# ADSP-2183xW_LPC register map
Vendor: Analog Devices; Series: ADSP-2183xW_LPC; File version: 3.0.3.517
CPU: 
Registers are 32-bit, read-write, reset 0x0 unless marked. A register's access mark holds for its fields unless they carry their own. Offsets are from the block's base; [hi:lo] are bit positions; {n}, {i} and the like mark numbered series; 'fields as' and 'values as' point back to an identical list.

## FIR0 — The FIR accelerator
Base 0x310C3000
Same registers: FIR1 0x310BF000
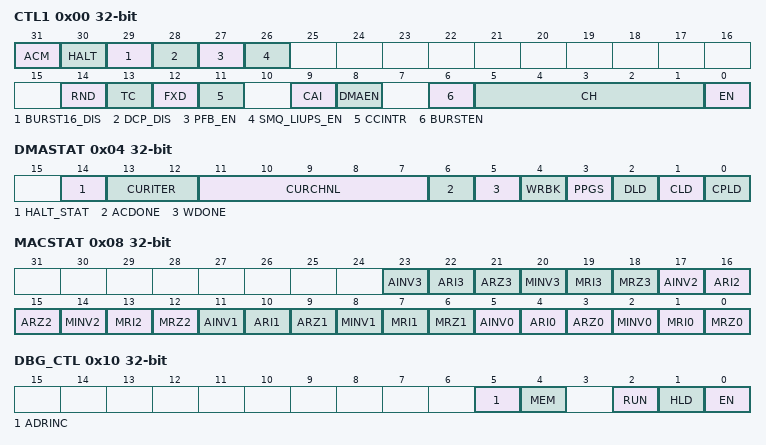
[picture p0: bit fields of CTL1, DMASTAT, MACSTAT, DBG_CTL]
0x00 CTL1 — FIR Global Control Register
  [31] ACM — Auto Configuration Mode
    0=LEGACY (Legacy Mode. Load TCB without the FIR_CTL1 register. Core intervention may be required.); 1=AUTOCONFIG (Auto Configuration Mode. Load TCB with the FIR_CTL1 register. Core intervention is not required.)
  [30] HALT — HALT (Pause Accelerator)
    0=RELEASE; 1=PAUSE
  [29] BURST16_DIS — Disable 16 Burst
  [28] DCP_DIS — Disable Data Coefficient Load in Parallel
  [27] PFB_EN — Enable PFB
  [26] SMQ_LIUPS_EN — Legacy I/P and O/P Index Update Scheme in SMART_Q Mode
  [14] RND — Rounding Mode
    0=TONEAREST (Round to Nearest); 1=TRUNCATE (Truncate (round towards zero))
  [13] TC — Two's-Complement
  [12] FXD — Fixed-Point Accelerator Select
  [11] CCINTR — Channel Complete Interrupt
  [9] CAI — Channel Auto Iterate
  [8] DMAEN — DMA Enable
  [6] BURSTEN range 0x00000000..0x00000001 — Burst Mode Select
  [5:1] CH — Number of Channels
  [0] EN — FIR Enable
0x04 DMASTAT — FIR DMA Status Register
  [14] HALT_STAT ro — Accelerator HALT Status
  [13:12] CURITER ro — Current MAC Iteration
  [11:7] CURCHNL ro — Current Channel
  [6] ACDONE ro — All Channels Done
  [5] WDONE ro — Channel Done
  [4] WRBK ro — Writing Back
  [3] PPGS ro — MAC Processing in Progress
  [2] DLD ro — Data Preload
  [1] CLD ro — Coefficient Loading
  [0] CPLD ro — Chain Pointer Loading Status
0x08 MACSTAT — FIR MAC Status Register
  [6n+5] AINV{n} ro (n=0..3) — Addition Invalid
  [6n+4] ARI{n} ro (n=0..3) — Adder Result Overflow
  [6n+3] ARZ{n} ro (n=0..3) — Adder Result Underflow
  [6n+2] MINV{n} ro (n=0..3) — Multiply Invalid
  [6n+1] MRI{n} ro (n=0..3) — Multiplier Result Overflow
  [6n] MRZ{n} ro (n=0..3) — Multiplier Result Underflow
0x10 DBG_CTL — FIR Debug Control Register
  [5] ADRINC range 0x00000000..0x00000001 — Address Auto Increment
  [4] MEM range 0x00000000..0x00000001 — Local Memory Access
  [2] RUN range 0x00000000..0x00000001 — Release MAC
  [1] HLD — Hold
  [0] EN — Debug Mode Enable
0x14 DBG_ADDR — Debug Address Register
  [10:0] VALUE range 0x00000000..0x000007FF — Debug Address, Coefficient Memory Select
0x18 DBG_WRDAT — FIR Debug Data Write Register
  [31:0] VALUE range 0x00000000..0xFFFFFFFF — Debug Write Data
0x1C DBG_RDDAT — FIR Debug Data Read Register
  [31:0] VALUE range 0x00000000..0xFFFFFFFF — Debug Read Data
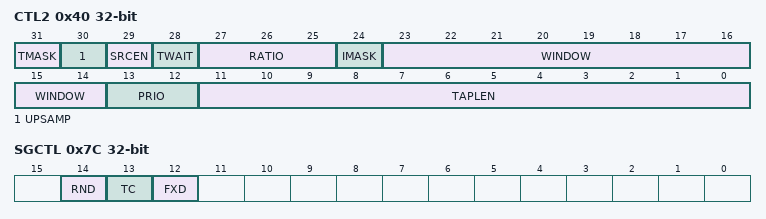
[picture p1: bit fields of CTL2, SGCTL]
0x40 CTL2 — FIR Channel Control Register
  [31] TMASK — Trigger Mask
    0=TMASK_EN (Enable); 1=TMASK_DIS (Mask)
  [30] UPSAMP — Up Sampling Enable
  [29] SRCEN — Sample Rate Conversion Enable
  [28] TWAIT — Wait for Trigger
    0=DIS (Disable wait for trigger for the channel); 1=ENA (Enable wait for the external trigger assertion)
  [27:25] RATIO range 0x00000000..0x00000007 — Up/Down Sampling Ratio
  [24] IMASK — Interrupt Mask
    0=IMASK_ENA (Enable); 1=IMASK_DIS (Mask)
  [23:14] WINDOW range 0x00000000..0x000003FF — Window Size
  [13:12] PRIO — Priority Level
    0=LEVEL0 (Level 0 (lowest)); 1=LEVEL1; 2=LEVEL2; 3=LEVEL3 (Level 3 (highest))
  [11:0] TAPLEN range 0x00000000..0x00000FFF — Tap Length
0x44 INIDX — FIR Input Data Index Register
  [29:0] VALUE range 0x00000000..0x3FFFFFFF — Word Address with Lower 2 Bits Removed
0x48 INMOD — FIR Input Data Modifier Register
  [15:0] VALUE range 0x00000000..0x0000FFFF — 16-bit Input Data Buffer Modifier
0x4C INCNT — FIR Input Data Count Register
  [15:0] VALUE range 0x00000000..0x0000FFFF — 16-bit Input Data Count
0x50 INBASE — FIR Input Data Base Register
  fields as INIDX
0x54 OUTIDX — FIR Output Data Index Register
  fields as INIDX
0x58 OUTMOD — FIR Output Data Modifier Register
  [15:0] VALUE range 0x00000000..0x0000FFFF — 16-bit Output Data Modifier
0x5C OUTCNT — FIR Output Data Count Register
  [15:0] VALUE range 0x00000000..0x0000FFFF — 16-bit Output Buffer Count
0x60 OUTBASE — FIR Output Data Base Register
  fields as INIDX
0x64 COEFIDX — FIR Coefficient Index Register
  [29:0] VALUE range 0x00000000..0x3FFFFFFF — Word Addresses with Lower 2 Bits Removed
0x68 COEFMOD — FIR Coefficient Modifier Register
  [15:0] VALUE range 0x00000000..0x0000FFFF — 16-bit Coefficient Index Modifier
0x6C COEFCNT — FIR Coefficient Count Register
  [15:0] CCNT range 0x00000000..0x0000FFFF — 16-bit Coefficient Buffer Count
0x70 CHNPTR — FIR Chain Pointer Register
  [29:0] VALUE range 0x00000000..0x3FFFFFFF — Chain Pointer Address
0x74 SCTL1 — Software Control Register 1
  [31:0] VALUE range 0x00000000..0xFFFFFFFF — Software control field 1
0x78 SCTL2 — Software Control Register 2
  [31:0] VALUE range 0x00000000..0xFFFFFFFF — Software control field 2
0x7C SGCTL — Secondary Global Control Register
  [14] RND — Rounding Mode Select for Floating-Point Mode
  [13] TC — Two's-Complement Format Input Select
  [12] FXD — Fixed-Point Accelerator Select
